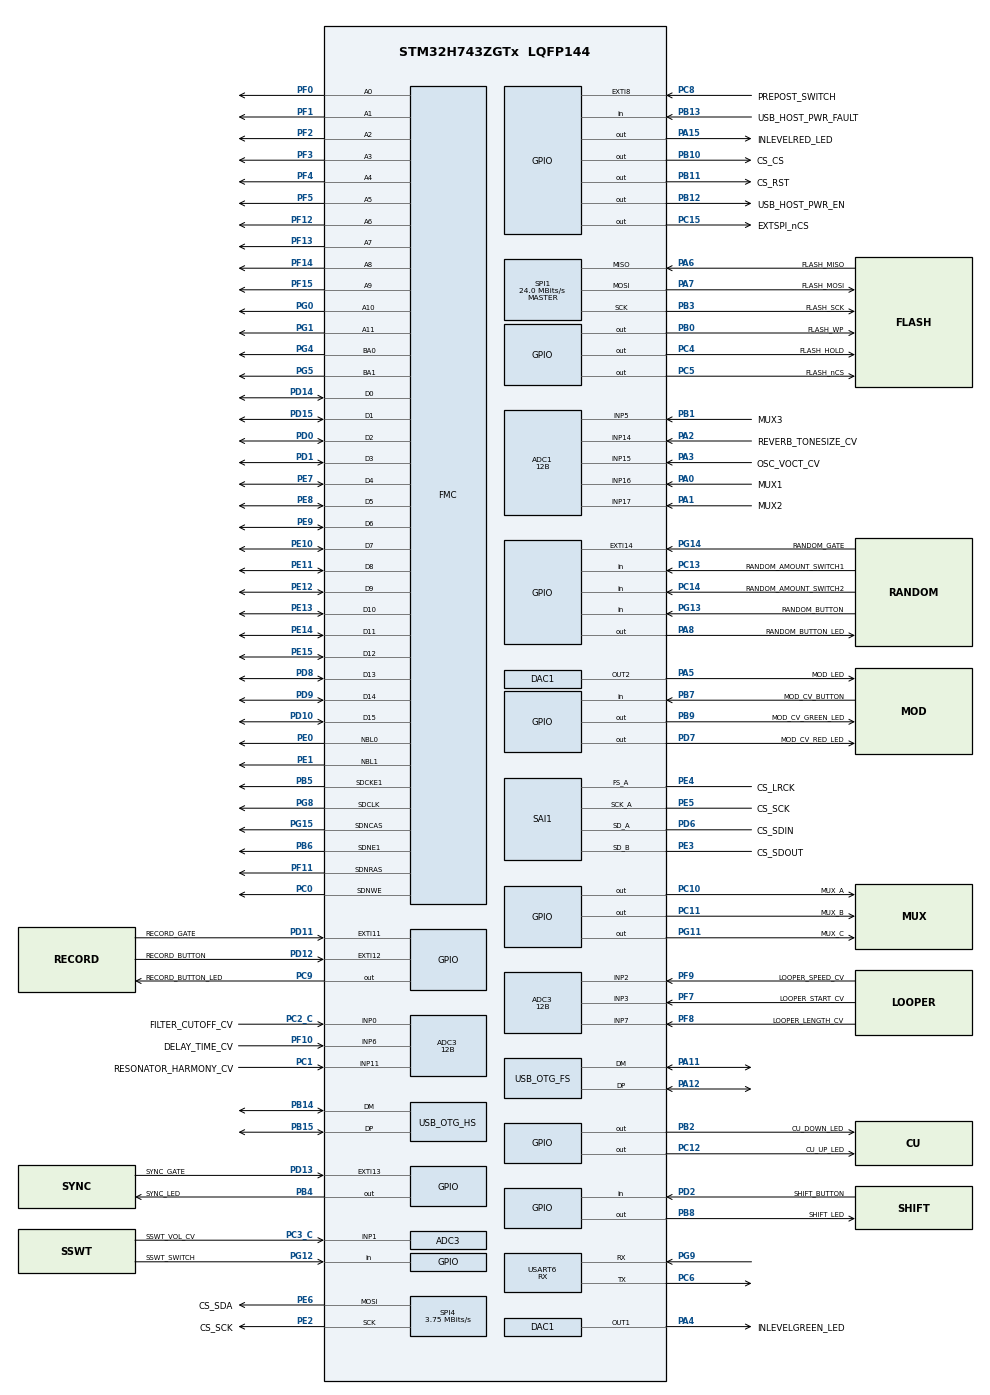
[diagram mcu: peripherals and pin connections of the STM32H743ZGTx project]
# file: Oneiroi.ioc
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ADC1.Channel-0\#ChannelRegularConversion=ADC_CHANNEL_14
ADC1.Channel-1\#ChannelRegularConversion=ADC_CHANNEL_15
ADC1.Channel-2\#ChannelRegularConversion=ADC_CHANNEL_16
ADC1.Channel-3\#ChannelRegularConversion=ADC_CHANNEL_17
ADC1.Channel-4\#ChannelRegularConversion=ADC_CHANNEL_5
ADC1.ClockPrescaler=ADC_CLOCK_ASYNC_DIV16
ADC1.ClockPrescalerADC3=ADC_CLOCK_ASYNC_DIV4
ADC1.ContinuousConvMode=ENABLE
ADC1.ConversionDataManagement=ADC_CONVERSIONDATA_DMA_CIRCULAR
ADC1.EOCSelection=ADC_EOC_SEQ_CONV
ADC1.NbrOfConversion=5
ADC1.NbrOfConversionFlag=1
ADC1.OffsetNumber-0\#ChannelRegularConversion=ADC_OFFSET_NONE
ADC1.OffsetNumber-1\#ChannelRegularConversion=ADC_OFFSET_NONE
ADC1.OffsetNumber-2\#ChannelRegularConversion=ADC_OFFSET_NONE
ADC1.OffsetNumber-3\#ChannelRegularConversion=ADC_OFFSET_NONE
ADC1.OffsetNumber-4\#ChannelRegularConversion=ADC_OFFSET_NONE
ADC1.OffsetSignedSaturation-0\#ChannelRegularConversion=DISABLE
ADC1.Overrun=ADC_OVR_DATA_OVERWRITTEN
ADC1.Rank-0\#ChannelRegularConversion=1
ADC1.Rank-1\#ChannelRegularConversion=2
ADC1.Rank-2\#ChannelRegularConversion=3
ADC1.Rank-3\#ChannelRegularConversion=4
ADC1.Rank-4\#ChannelRegularConversion=5
ADC1.Resolution=ADC_RESOLUTION_12B
ADC1.SamplingTime-0\#ChannelRegularConversion=ADC_SAMPLETIME_387CYCLES_5
ADC1.SamplingTime-1\#ChannelRegularConversion=ADC_SAMPLETIME_387CYCLES_5
ADC1.SamplingTime-2\#ChannelRegularConversion=ADC_SAMPLETIME_387CYCLES_5
ADC1.SamplingTime-3\#ChannelRegularConversion=ADC_SAMPLETIME_387CYCLES_5
ADC1.SamplingTime-4\#ChannelRegularConversion=ADC_SAMPLETIME_387CYCLES_5
ADC1.master=1
ADC3.Channel-10\#ChannelRegularConversion=ADC_CHANNEL_2
ADC3.Channel-4\#ChannelRegularConversion=ADC_CHANNEL_1
ADC3.Channel-5\#ChannelRegularConversion=ADC_CHANNEL_0
ADC3.Channel-6\#ChannelRegularConversion=ADC_CHANNEL_11
ADC3.Channel-7\#ChannelRegularConversion=ADC_CHANNEL_6
ADC3.Channel-8\#ChannelRegularConversion=ADC_CHANNEL_3
ADC3.Channel-9\#ChannelRegularConversion=ADC_CHANNEL_7
ADC3.ClockPrescaler=ADC_CLOCK_ASYNC_DIV16
ADC3.ClockPrescalerADC3=ADC_CLOCK_ASYNC_DIV4
ADC3.ContinuousConvMode=ENABLE
ADC3.ConversionDataManagement=ADC_CONVERSIONDATA_DMA_CIRCULAR
ADC3.EOCSelection=ADC_EOC_SEQ_CONV
ADC3.NbrOfConversion=7
ADC3.NbrOfConversionFlag=1
ADC3.OffsetNumber-10\#ChannelRegularConversion=ADC_OFFSET_NONE
ADC3.OffsetNumber-4\#ChannelRegularConversion=ADC_OFFSET_NONE
ADC3.OffsetNumber-5\#ChannelRegularConversion=ADC_OFFSET_NONE
ADC3.OffsetNumber-6\#ChannelRegularConversion=ADC_OFFSET_NONE
ADC3.OffsetNumber-7\#ChannelRegularConversion=ADC_OFFSET_NONE
ADC3.OffsetNumber-8\#ChannelRegularConversion=ADC_OFFSET_NONE
ADC3.OffsetNumber-9\#ChannelRegularConversion=ADC_OFFSET_NONE
ADC3.OffsetSignedSaturation-4\#ChannelRegularConversion=DISABLE
ADC3.Overrun=ADC_OVR_DATA_OVERWRITTEN
ADC3.Rank-10\#ChannelRegularConversion=7
ADC3.Rank-4\#ChannelRegularConversion=1
ADC3.Rank-5\#ChannelRegularConversion=2
ADC3.Rank-6\#ChannelRegularConversion=3
ADC3.Rank-7\#ChannelRegularConversion=4
ADC3.Rank-8\#ChannelRegularConversion=5
ADC3.Rank-9\#ChannelRegularConversion=6
ADC3.Resolution=ADC_RESOLUTION_12B
ADC3.SamplingTime-10\#ChannelRegularConversion=ADC_SAMPLETIME_387CYCLES_5
ADC3.SamplingTime-4\#ChannelRegularConversion=ADC_SAMPLETIME_387CYCLES_5
ADC3.SamplingTime-5\#ChannelRegularConversion=ADC_SAMPLETIME_387CYCLES_5
ADC3.SamplingTime-6\#ChannelRegularConversion=ADC_SAMPLETIME_387CYCLES_5
ADC3.SamplingTime-7\#ChannelRegularConversion=ADC_SAMPLETIME_387CYCLES_5
ADC3.SamplingTime-8\#ChannelRegularConversion=ADC_SAMPLETIME_387CYCLES_5
ADC3.SamplingTime-9\#ChannelRegularConversion=ADC_SAMPLETIME_387CYCLES_5
DAC1.DAC1_OutputBuffer-DAC_OUT1=DAC_OUTPUTBUFFER_ENABLE
DAC1.DAC2_OutputBuffer-DAC_OUT2=DAC_OUTPUTBUFFER_ENABLE
DAC1.DAC_Channel-DAC_OUT1=DAC_CHANNEL_1
DAC1.DAC_Channel-DAC_OUT2=DAC_CHANNEL_2
Dma.ADC1.2.Direction=DMA_PERIPH_TO_MEMORY
Dma.ADC1.2.EventEnable=DISABLE
Dma.ADC1.2.FIFOMode=DMA_FIFOMODE_DISABLE
Dma.ADC1.2.Instance=DMA1_Stream1
Dma.ADC1.2.MemDataAlignment=DMA_MDATAALIGN_HALFWORD
Dma.ADC1.2.MemInc=DMA_MINC_ENABLE
Dma.ADC1.2.Mode=DMA_CIRCULAR
Dma.ADC1.2.PeriphDataAlignment=DMA_PDATAALIGN_HALFWORD
Dma.ADC1.2.PeriphInc=DMA_PINC_DISABLE
Dma.ADC1.2.Polarity=HAL_DMAMUX_REQ_GEN_RISING
Dma.ADC1.2.Priority=DMA_PRIORITY_LOW
Dma.ADC1.2.RequestNumber=1
Dma.ADC1.2.SignalID=NONE
Dma.ADC1.2.SyncEnable=DISABLE
Dma.ADC1.2.SyncPolarity=HAL_DMAMUX_SYNC_NO_EVENT
Dma.ADC1.2.SyncRequestNumber=1
Dma.ADC1.2.SyncSignalID=NONE
Dma.ADC3.3.Direction=DMA_PERIPH_TO_MEMORY
Dma.ADC3.3.EventEnable=DISABLE
Dma.ADC3.3.FIFOMode=DMA_FIFOMODE_DISABLE
Dma.ADC3.3.Instance=DMA1_Stream0
Dma.ADC3.3.MemDataAlignment=DMA_MDATAALIGN_HALFWORD
Dma.ADC3.3.MemInc=DMA_MINC_ENABLE
Dma.ADC3.3.Mode=DMA_CIRCULAR
Dma.ADC3.3.PeriphDataAlignment=DMA_PDATAALIGN_HALFWORD
Dma.ADC3.3.PeriphInc=DMA_PINC_DISABLE
Dma.ADC3.3.Polarity=HAL_DMAMUX_REQ_GEN_RISING
Dma.ADC3.3.Priority=DMA_PRIORITY_LOW
Dma.ADC3.3.RequestNumber=1
Dma.ADC3.3.SignalID=NONE
Dma.ADC3.3.SyncEnable=DISABLE
Dma.ADC3.3.SyncPolarity=HAL_DMAMUX_SYNC_NO_EVENT
Dma.ADC3.3.SyncRequestNumber=1
Dma.ADC3.3.SyncSignalID=NONE
Dma.Request0=SAI1_A
Dma.Request1=SAI1_B
Dma.Request2=ADC1
Dma.Request3=ADC3
Dma.SAI1_A.0.Direction=DMA_MEMORY_TO_PERIPH
Dma.SAI1_A.0.EventEnable=DISABLE
Dma.SAI1_A.0.FIFOMode=DMA_FIFOMODE_DISABLE
Dma.SAI1_A.0.Instance=DMA2_Stream1
Dma.SAI1_A.0.MemDataAlignment=DMA_MDATAALIGN_WORD
Dma.SAI1_A.0.MemInc=DMA_MINC_ENABLE
Dma.SAI1_A.0.Mode=DMA_CIRCULAR
Dma.SAI1_A.0.PeriphDataAlignment=DMA_PDATAALIGN_WORD
Dma.SAI1_A.0.PeriphInc=DMA_PINC_DISABLE
Dma.SAI1_A.0.Polarity=HAL_DMAMUX_REQ_GEN_RISING
Dma.SAI1_A.0.Priority=DMA_PRIORITY_HIGH
Dma.SAI1_A.0.RequestNumber=1
Dma.SAI1_A.0.SignalID=NONE
Dma.SAI1_A.0.SyncEnable=DISABLE
Dma.SAI1_A.0.SyncPolarity=HAL_DMAMUX_SYNC_NO_EVENT
Dma.SAI1_A.0.SyncRequestNumber=1
Dma.SAI1_A.0.SyncSignalID=NONE
Dma.SAI1_B.1.Direction=DMA_PERIPH_TO_MEMORY
Dma.SAI1_B.1.EventEnable=DISABLE
Dma.SAI1_B.1.FIFOMode=DMA_FIFOMODE_DISABLE
Dma.SAI1_B.1.Instance=DMA2_Stream4
Dma.SAI1_B.1.MemDataAlignment=DMA_MDATAALIGN_WORD
Dma.SAI1_B.1.MemInc=DMA_MINC_ENABLE
Dma.SAI1_B.1.Mode=DMA_CIRCULAR
Dma.SAI1_B.1.PeriphDataAlignment=DMA_PDATAALIGN_WORD
Dma.SAI1_B.1.PeriphInc=DMA_PINC_DISABLE
Dma.SAI1_B.1.Polarity=HAL_DMAMUX_REQ_GEN_RISING
Dma.SAI1_B.1.Priority=DMA_PRIORITY_HIGH
Dma.SAI1_B.1.RequestNumber=1
Dma.SAI1_B.1.SignalID=NONE
Dma.SAI1_B.1.SyncEnable=DISABLE
Dma.SAI1_B.1.SyncPolarity=HAL_DMAMUX_SYNC_NO_EVENT
Dma.SAI1_B.1.SyncRequestNumber=1
Dma.SAI1_B.1.SyncSignalID=NONE
FMC.CASLatency1=FMC_SDRAM_CAS_LATENCY_3
FMC.ExitSelfRefreshDelay1=6
FMC.LoadToActiveDelay1=2
FMC.RCDDelay1=2
FMC.RPDelay1=2
FMC.ReadBurst1=FMC_SDRAM_RBURST_ENABLE
FMC.ReadPipeDelay1=FMC_SDRAM_RPIPE_DELAY_0
FMC.RowCycleDelay1=6
FMC.SDClockPeriod1=FMC_SDRAM_CLOCK_PERIOD_2
FMC.SelfRefreshTime1=4
FMC.WriteRecoveryTime1=2
FREERTOS.INCLUDE_vTaskDelayUntil=1
FREERTOS.MEMORY_ALLOCATION=2
FREERTOS.Tasks01=defaultTask,0,1024,StartDefaultTask,Default,NULL,Dynamic,NULL,NULL
FREERTOS.configCHECK_FOR_STACK_OVERFLOW=2
FREERTOS.configENABLE_BACKWARD_COMPATIBILITY=0
FREERTOS.configTOTAL_HEAP_SIZE=8192
FREERTOS.configUSE_MALLOC_FAILED_HOOK=1
FREERTOS.configUSE_MUTEXES=0
FREERTOS.configUSE_PREEMPTION=0
Mcu.Family=STM32H7
Mcu.Name=STM32H743ZGTx
Mcu.Package=LQFP144
NVIC.ADC3_IRQn=true\:5\:0\:false\:false\:true\:true\:true\:true\:true
NVIC.ADC_IRQn=true\:5\:0\:false\:false\:true\:true\:true\:true\:true
NVIC.DMA1_Stream0_IRQn=true\:5\:0\:false\:false\:true\:true\:false\:true\:true
NVIC.DMA1_Stream1_IRQn=true\:5\:0\:false\:false\:true\:true\:false\:true\:true
NVIC.DMA2_Stream1_IRQn=true\:5\:0\:true\:false\:true\:true\:true\:true\:true
NVIC.DMA2_Stream4_IRQn=true\:5\:0\:true\:false\:true\:true\:true\:true\:true
NVIC.EXTI15_10_IRQn=true\:15\:0\:true\:false\:true\:true\:true\:true\:true
NVIC.EXTI9_5_IRQn=true\:15\:0\:true\:false\:true\:true\:true\:true\:true
NVIC.OTG_FS_IRQn=true\:10\:0\:true\:false\:true\:true\:true\:true\:true
NVIC.OTG_HS_IRQn=true\:10\:0\:true\:false\:true\:true\:true\:true\:true
NVIC.PriorityGroup=NVIC_PRIORITYGROUP_4
PA0.GPIO_Label=MUX1
PA0.Mode=IN16-Single-Ended
PA0.Signal=ADC1_INP16
PA1.GPIO_Label=MUX2
PA1.Mode=IN17-Single-Ended
PA1.Signal=ADC1_INP17
PA11.Mode=Device_Only
PA11.Signal=USB_OTG_FS_DM
PA12.Mode=Device_Only
PA12.Signal=USB_OTG_FS_DP
PA13\ (JTMS/SWDIO).Mode=Serial_Wire
PA13\ (JTMS/SWDIO).Signal=DEBUG_JTMS-SWDIO
PA14\ (JTCK/SWCLK).Mode=Serial_Wire
PA14\ (JTCK/SWCLK).Signal=DEBUG_JTCK-SWCLK
PA15\ (JTDI).GPIO_Label=INLEVELRED_LED
PA15\ (JTDI).Signal=GPIO_Output
PA2.GPIO_Label=REVERB_TONESIZE_CV
PA2.Signal=ADCx_INP14
PA3.GPIO_Label=OSC_VOCT_CV
PA3.Signal=ADCx_INP15
PA4.GPIO_Label=INLEVELGREEN_LED
PA4.Signal=COMP_DAC11_group
PA5.GPIO_Label=MOD_LED
PA5.Signal=COMP_DAC12_group
PA6.GPIO_Label=FLASH_MISO
PA6.Mode=Full_Duplex_Master
PA6.Signal=SPI1_MISO
PA7.GPIO_Label=FLASH_MOSI
PA7.Mode=Full_Duplex_Master
PA7.Signal=SPI1_MOSI
PA8.GPIO_Label=RANDOM_BUTTON_LED
PA8.Signal=GPIO_Output
PB0.GPIO_Label=FLASH_WP
PB0.Signal=GPIO_Output
PB1.GPIO_Label=MUX3
PB1.Signal=ADCx_INP5
PB10.GPIO_Label=CS_CS
PB10.Signal=GPIO_Output
PB11.GPIO_Label=CS_RST
PB11.Signal=GPIO_Output
PB12.GPIO_Label=USB_HOST_PWR_EN
PB12.Signal=GPIO_Output
PB13.GPIO_Label=USB_HOST_PWR_FAULT
PB13.GPIO_PuPd=GPIO_PULLUP
PB13.Signal=GPIO_Input
PB14.Mode=Host_FS
PB14.Signal=USB_OTG_HS_DM
PB15.Mode=Host_FS
PB15.Signal=USB_OTG_HS_DP
PB2.GPIO_Label=CU_DOWN_LED
PB2.Signal=GPIO_Output
PB3\ (JTDO/TRACESWO).GPIO_Label=FLASH_SCK
PB3\ (JTDO/TRACESWO).Mode=Full_Duplex_Master
PB3\ (JTDO/TRACESWO).Signal=SPI1_SCK
PB4\ (NJTRST).GPIO_Label=SYNC_LED
PB4\ (NJTRST).Signal=GPIO_Output
PB5.Mode=SdramChipSelect2_1
PB5.Signal=FMC_SDCKE1
PB6.Mode=SdramChipSelect2_1
PB6.Signal=FMC_SDNE1
PB7.GPIO_Label=MOD_CV_BUTTON
PB7.GPIO_PuPd=GPIO_PULLUP
PB7.Signal=GPIO_Input
PB8.GPIO_Label=SHIFT_LED
PB8.Signal=GPIO_Output
PB9.GPIO_Label=MOD_CV_GREEN_LED
PB9.Signal=GPIO_Output
PC0.Signal=FMC_SDNWE
PC1.GPIO_Label=RESONATOR_HARMONY_CV
PC1.Signal=ADCx_INP11
PC10.GPIO_Label=MUX_A
PC10.Signal=GPIO_Output
PC11.GPIO_Label=MUX_B
PC11.Signal=GPIO_Output
PC12.GPIO_Label=CU_UP_LED
PC12.Signal=GPIO_Output
PC13.GPIO_Label=RANDOM_AMOUNT_SWITCH1
PC13.GPIO_PuPd=GPIO_PULLUP
PC13.Signal=GPIO_Input
PC14-OSC32_IN\ (OSC32_IN).GPIO_Label=RANDOM_AMOUNT_SWITCH2
PC14-OSC32_IN\ (OSC32_IN).GPIO_PuPd=GPIO_PULLUP
PC14-OSC32_IN\ (OSC32_IN).Signal=GPIO_Input
PC15-OSC32_OUT\ (OSC32_OUT).GPIO_Label=EXTSPI_nCS
PC15-OSC32_OUT\ (OSC32_OUT).Signal=GPIO_Output
PC2_C.GPIO_Label=FILTER_CUTOFF_CV
PC2_C.Mode=IN0-Single-Ended
PC2_C.Signal=ADC3_INP0
PC3_C.GPIO_Label=SSWT_VOL_CV
PC3_C.Mode=IN1-Single-Ended
PC3_C.Signal=ADC3_INP1
PC4.GPIO_Label=FLASH_HOLD
PC4.Signal=GPIO_Output
PC5.GPIO_Label=FLASH_nCS
PC5.Signal=GPIO_Output
PC6.Mode=Asynchronous
PC6.Signal=USART6_TX
PC8.GPIO_Label=PREPOST_SWITCH
PC8.GPIO_ModeDefaultEXTI=GPIO_MODE_IT_RISING_FALLING
PC8.GPIO_PuPd=GPIO_PULLUP
PC8.Signal=GPXTI8
PC9.GPIO_Label=RECORD_BUTTON_LED
PC9.Signal=GPIO_Output
PD0.Signal=FMC_D2_DA2
PD1.Signal=FMC_D3_DA3
PD10.Signal=FMC_D15_DA15
PD11.GPIO_Label=RECORD_GATE
PD11.GPIO_ModeDefaultEXTI=GPIO_MODE_IT_RISING_FALLING
PD11.GPIO_PuPd=GPIO_PULLUP
PD11.Signal=GPXTI11
PD12.GPIO_Label=RECORD_BUTTON
PD12.GPIO_ModeDefaultEXTI=GPIO_MODE_IT_RISING_FALLING
PD12.GPIO_PuPd=GPIO_PULLUP
PD12.Signal=GPXTI12
PD13.GPIO_Label=SYNC_GATE
PD13.GPIO_ModeDefaultEXTI=GPIO_MODE_IT_RISING_FALLING
PD13.GPIO_PuPd=GPIO_PULLUP
PD13.Signal=GPXTI13
PD14.Signal=FMC_D0_DA0
PD15.Signal=FMC_D1_DA1
PD2.GPIO_Label=SHIFT_BUTTON
PD2.GPIO_PuPd=GPIO_PULLUP
PD2.Signal=GPIO_Input
PD6.GPIO_Label=CS_SDIN
PD6.GPIO_Speed=GPIO_SPEED_FREQ_VERY_HIGH
PD6.Mode=SAI_A_AsyncSlave
PD6.Signal=SAI1_SD_A
PD7.GPIO_Label=MOD_CV_RED_LED
PD7.Signal=GPIO_Output
PD8.Signal=FMC_D13_DA13
PD9.Signal=FMC_D14_DA14
PE0.Signal=FMC_NBL0
PE1.Signal=FMC_NBL1
PE10.Signal=FMC_D7_DA7
PE11.Signal=FMC_D8_DA8
PE12.Signal=FMC_D9_DA9
PE13.Signal=FMC_D10_DA10
PE14.Signal=FMC_D11_DA11
PE15.Signal=FMC_D12_DA12
PE2.GPIO_Label=CS_SCK
PE2.Mode=TX_Only_Simplex_Unidirect_Master
PE2.Signal=SPI4_SCK
PE3.GPIO_Label=CS_SDOUT
PE3.GPIO_Speed=GPIO_SPEED_FREQ_VERY_HIGH
PE3.Mode=SAI_B_SyncSlave
PE3.Signal=SAI1_SD_B
PE4.GPIO_Label=CS_LRCK
PE4.GPIO_Speed=GPIO_SPEED_FREQ_VERY_HIGH
PE4.Mode=SAI_A_AsyncSlave
PE4.Signal=SAI1_FS_A
PE5.GPIO_Label=CS_SCK
PE5.GPIO_Speed=GPIO_SPEED_FREQ_VERY_HIGH
PE5.Mode=SAI_A_AsyncSlave
PE5.Signal=SAI1_SCK_A
PE6.GPIO_Label=CS_SDA
PE6.Mode=TX_Only_Simplex_Unidirect_Master
PE6.Signal=SPI4_MOSI
PE7.Signal=FMC_D4_DA4
PE8.Signal=FMC_D5_DA5
PE9.Signal=FMC_D6_DA6
PF0.Signal=FMC_A0
PF1.Signal=FMC_A1
PF10.GPIO_Label=DELAY_TIME_CV
PF10.Mode=IN6-Single-Ended
PF10.Signal=ADC3_INP6
PF11.Signal=FMC_SDNRAS
PF12.Signal=FMC_A6
PF13.Signal=FMC_A7
PF14.Signal=FMC_A8
PF15.Signal=FMC_A9
PF2.Signal=FMC_A2
PF3.Signal=FMC_A3
PF4.Signal=FMC_A4
PF5.Signal=FMC_A5
PF7.GPIO_Label=LOOPER_START_CV
PF7.Mode=IN3-Single-Ended
PF7.Signal=ADC3_INP3
PF8.GPIO_Label=LOOPER_LENGTH_CV
PF8.Mode=IN7-Single-Ended
PF8.Signal=ADC3_INP7
PF9.GPIO_Label=LOOPER_SPEED_CV
PF9.Mode=IN2-Single-Ended
PF9.Signal=ADC3_INP2
PG0.Signal=FMC_A10
PG1.Signal=FMC_A11
PG11.GPIO_Label=MUX_C
PG11.Signal=GPIO_Output
PG12.GPIO_Label=SSWT_SWITCH
PG12.GPIO_PuPd=GPIO_PULLUP
PG12.Signal=GPIO_Input
PG13.GPIO_Label=RANDOM_BUTTON
PG13.GPIO_PuPd=GPIO_PULLUP
PG13.Signal=GPIO_Input
PG14.GPIO_Label=RANDOM_GATE
PG14.GPIO_ModeDefaultEXTI=GPIO_MODE_IT_RISING_FALLING
PG14.GPIO_PuPd=GPIO_PULLUP
PG14.Signal=GPXTI14
PG15.Signal=FMC_SDNCAS
PG4.Signal=FMC_A14_BA0
PG5.Signal=FMC_A15_BA1
PG8.Signal=FMC_SDCLK
PG9.Mode=Asynchronous
PG9.Signal=USART6_RX
PH0-OSC_IN\ (PH0).GPIO_Label=OSC1
PH0-OSC_IN\ (PH0).Mode=HSE-External-Oscillator
PH0-OSC_IN\ (PH0).Signal=RCC_OSC_IN
PH1-OSC_OUT\ (PH1).GPIO_Label=OSC2
PH1-OSC_OUT\ (PH1).Mode=HSE-External-Oscillator
PH1-OSC_OUT\ (PH1).Signal=RCC_OSC_OUT
ProjectManager.HeapSize=0x200
ProjectManager.StackSize=0x400
ProjectManager.TargetToolchain=Makefile
RCC.48MHZClocksFreq_Value=48000000
RCC.ADCFreq_Value=30000000
RCC.AHBFreq_Value=168000000
RCC.APB1CLKDivider=RCC_HCLK_DIV4
RCC.APB1Freq_Value=120000000
RCC.APB1TimFreq_Value=84000000
RCC.APB2CLKDivider=RCC_HCLK_DIV2
RCC.APB2Freq_Value=120000000
RCC.APB2TimFreq_Value=168000000
RCC.APB3Freq_Value=120000000
RCC.APB4Freq_Value=120000000
RCC.CortexFreq_Value=480000000
RCC.D1PPRE=RCC_APB3_DIV2
RCC.D2PPRE1=RCC_APB1_DIV2
RCC.D2PPRE2=RCC_APB2_DIV2
RCC.D3PPRE=RCC_APB4_DIV2
RCC.DIVM1=5
RCC.DIVM2=2
RCC.DIVN1=192
RCC.DIVN2=12
RCC.DIVP2=5
RCC.DIVQ1=20
RCC.HCLKFreq_Value=240000000
RCC.HPRE=RCC_HCLK_DIV2
RCC.HSE_VALUE=25000000
RCC.HSI_VALUE=16000000
RCC.LSE_VALUE=32768
RCC.PLLFRACN=0
RCC.PLLM=25
RCC.PLLN=336
RCC.PLLQ=7
RCC.PLLSAIN=100
RCC.SYSCLKFreq_VALUE=480000000
RCC.SYSCLKSource=RCC_SYSCLKSOURCE_PLLCLK
RCC.USBFreq_Value=48000000
RCC.VCOOutputFreq_Value=336000000
SAI1.AudioMode-SAI_A_AsyncSlave=SAI_MODESLAVE_TX
SAI1.BasicDataSize-SAI_A_AsyncSlave=SAI_PROTOCOL_DATASIZE_24BIT
SAI1.BasicDataSize-SAI_B_SyncSlave=SAI_PROTOCOL_DATASIZE_24BIT
SAI1.InitProtocol-SAI_A_AsyncSlave=Enable
SAI1.InitProtocol-SAI_B_SyncSlave=Enable
SAI1.Instance-SAI_A_AsyncSlave=SAI$Index_Block_A
SAI1.Instance-SAI_B_SyncSlave=SAI$Index_Block_B
SAI1.VirtualMode-SAI_A_AsyncSlave=VM_SLAVE
SAI1.VirtualMode-SAI_B_SyncSlave=VM_SLAVE
SAI1.VirtualProtocol-SAI_A_BASIC=VM_BASIC_PROTOCOL
SAI1.VirtualProtocol-SAI_B_BASIC=VM_BASIC_PROTOCOL
SH.ADCx_INP11.0=ADC3_INP11,IN11-Single-Ended
SH.ADCx_INP14.0=ADC1_INP14,IN14-Single-Ended
SH.ADCx_INP15.0=ADC1_INP15,IN15-Single-Ended
SH.ADCx_INP5.0=ADC1_INP5,IN5-Single-Ended
SH.COMP_DAC11_group.0=DAC1_OUT1,DAC_OUT1
SH.COMP_DAC12_group.0=DAC1_OUT2,DAC_OUT2
SH.FMC_A0.0=FMC_A0,12b-sda1
SH.FMC_A1.0=FMC_A1,12b-sda1
SH.FMC_A10.0=FMC_A10,12b-sda1
SH.FMC_A11.0=FMC_A11,12b-sda1
SH.FMC_A14_BA0.0=FMC_BA0,FourSdramBanks1
SH.FMC_A15_BA1.0=FMC_BA1,FourSdramBanks1
SH.FMC_A2.0=FMC_A2,12b-sda1
SH.FMC_A3.0=FMC_A3,12b-sda1
SH.FMC_A4.0=FMC_A4,12b-sda1
SH.FMC_A5.0=FMC_A5,12b-sda1
SH.FMC_A6.0=FMC_A6,12b-sda1
SH.FMC_A7.0=FMC_A7,12b-sda1
SH.FMC_A8.0=FMC_A8,12b-sda1
SH.FMC_A9.0=FMC_A9,12b-sda1
SH.FMC_D0_DA0.0=FMC_D0,sd-16b-d1
SH.FMC_D10_DA10.0=FMC_D10,sd-16b-d1
SH.FMC_D11_DA11.0=FMC_D11,sd-16b-d1
SH.FMC_D12_DA12.0=FMC_D12,sd-16b-d1
SH.FMC_D13_DA13.0=FMC_D13,sd-16b-d1
SH.FMC_D14_DA14.0=FMC_D14,sd-16b-d1
SH.FMC_D15_DA15.0=FMC_D15,sd-16b-d1
SH.FMC_D1_DA1.0=FMC_D1,sd-16b-d1
SH.FMC_D2_DA2.0=FMC_D2,sd-16b-d1
SH.FMC_D3_DA3.0=FMC_D3,sd-16b-d1
SH.FMC_D4_DA4.0=FMC_D4,sd-16b-d1
SH.FMC_D5_DA5.0=FMC_D5,sd-16b-d1
SH.FMC_D6_DA6.0=FMC_D6,sd-16b-d1
SH.FMC_D7_DA7.0=FMC_D7,sd-16b-d1
SH.FMC_D8_DA8.0=FMC_D8,sd-16b-d1
SH.FMC_D9_DA9.0=FMC_D9,sd-16b-d1
SH.FMC_NBL0.0=FMC_NBL0,Sd2ByteEnable1
SH.FMC_NBL1.0=FMC_NBL1,Sd2ByteEnable1
SH.FMC_SDCLK.0=FMC_SDCLK,12b-sda1
SH.FMC_SDNCAS.0=FMC_SDNCAS,12b-sda1
SH.FMC_SDNRAS.0=FMC_SDNRAS,12b-sda1
SH.FMC_SDNWE.0=FMC_SDNWE,12b-sda1
SPI1.BaudRatePrescaler=SPI_BAUDRATEPRESCALER_2
SPI1.CalculateBaudRate=24.0 MBits/s
SPI1.DataSize=SPI_DATASIZE_8BIT
SPI1.Direction=SPI_DIRECTION_2LINES
SPI1.Mode=SPI_MODE_MASTER
SPI1.NSSPMode=SPI_NSS_PULSE_DISABLE
SPI1.VirtualType=VM_MASTER
SPI4.BaudRatePrescaler=SPI_BAUDRATEPRESCALER_32
SPI4.CalculateBaudRate=3.75 MBits/s
SPI4.DataSize=SPI_DATASIZE_8BIT
SPI4.Direction=SPI_DIRECTION_2LINES_TXONLY
SPI4.Mode=SPI_MODE_MASTER
SPI4.NSSPMode=SPI_NSS_PULSE_DISABLE
SPI4.VirtualType=VM_MASTER
USART6.Mode=MODE_RX
USART6.VirtualMode-Asynchronous=VM_ASYNC
USB_OTG_FS.VirtualMode=Device_Only
USB_OTG_HS.VirtualMode-Host_FS=Host_FS
VP_FREERTOS_VS_CMSIS_V1.Mode=CMSIS_V1
VP_RTC_VS_RTC_Activate.Mode=RTC_Enabled
VP_SAI1_VP_$IpInstance_SAIA_SAI_BASIC.Mode=SAI_A_BASIC
VP_SAI1_VP_$IpInstance_SAIB_SAI_BASIC.Mode=SAI_B_BASIC
board=custom

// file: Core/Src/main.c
/* USER CODE BEGIN Header */
/**
  ******************************************************************************
  * @file           : main.c
  * @brief          : Main program body
  ******************************************************************************
  * @attention
  *
  * Copyright (c) 2023 STMicroelectronics.
  * All rights reserved.
  *
  * This software is licensed under terms that can be found in the LICENSE file
  * in the root directory of this software component.
  * If no LICENSE file comes with this software, it is provided AS-IS.
  *
  ******************************************************************************
  */
/* USER CODE END Header */
#include "main.h"
#include "cmsis_os.h"

/* USER CODE BEGIN Includes */

#include "errorhandlers.h"  // 5/6/2023

#ifdef DEBUG
#include <stdio.h>
#endif

/* USER CODE END Includes */

ADC_HandleTypeDef hadc1;
ADC_HandleTypeDef hadc3;
DMA_HandleTypeDef hdma_adc1;
DMA_HandleTypeDef hdma_adc3;

DAC_HandleTypeDef hdac1;

RTC_HandleTypeDef hrtc;

SAI_HandleTypeDef hsai_BlockA1;
SAI_HandleTypeDef hsai_BlockB1;
DMA_HandleTypeDef hdma_sai1_a;
DMA_HandleTypeDef hdma_sai1_b;

SPI_HandleTypeDef hspi1;
SPI_HandleTypeDef hspi4;

UART_HandleTypeDef huart6;

PCD_HandleTypeDef hpcd_USB_OTG_FS;
HCD_HandleTypeDef hhcd_USB_OTG_HS;

SDRAM_HandleTypeDef hsdram1;

osThreadId defaultTaskHandle;

void SystemClock_Config(void);
void PeriphCommonClock_Config(void);
static void MX_GPIO_Init(void);
static void MX_DMA_Init(void);
static void MX_RTC_Init(void);
static void MX_SPI1_Init(void);
static void MX_SPI4_Init(void);
static void MX_USB_OTG_FS_PCD_Init(void);
static void MX_USB_OTG_HS_HCD_Init(void);
static void MX_SAI1_Init(void);
static void MX_ADC3_Init(void);
static void MX_DAC1_Init(void);
static void MX_FMC_Init(void);
static void MX_USART6_UART_Init(void);
static void MX_ADC1_Init(void);
void StartDefaultTask(void const * argument);

/* USER CODE BEGIN PFP */
/* Private function prototypes -----------------------------------------------*/

void setup(void);
void loop(void);
void SDRAM_Initialization_Sequence(SDRAM_HandleTypeDef *hsdram);
void initialise_monitor_handles(void);
void MPU_Config(void);

/* USER CODE END PFP */

int main(void)
{
  /* USER CODE BEGIN 1 */

#ifdef DEBUG
#warning "DEBUG uses printf and semihosting!"
  if(CoreDebug->DHCSR & 0x01)
    initialise_monitor_handles(); // remove when not semi-hosting
  printf("showtime\n");
#endif
#ifdef USE_ICACHE
  /* Enable I-Cache-------------------------------------------------------------*/
  /* After reset, you must invalidate each cache before enabling (SCB_EnableICache) it. */
  SCB_InvalidateICache();
  SCB_EnableICache();
#endif
#ifdef USE_DCACHE
  /* Enable D-Cache-------------------------------------------------------------*/
  /* Before enabling the data cache, you must invalidate the entire data cache (SCB_InvalidateDCache), because external memory might have changed from when the cache was disabled. */
  SCB_InvalidateDCache();
  SCB_EnableDCache();
#endif

  /* Enable D2 domain SRAM Clocks */
  __HAL_RCC_D2SRAM1_CLK_ENABLE();
  __HAL_RCC_D2SRAM2_CLK_ENABLE();
  __HAL_RCC_D2SRAM3_CLK_ENABLE();

  /* USER CODE END 1 */

  /* MCU Configuration--------------------------------------------------------*/

  /* Reset of all peripherals, Initializes the Flash interface and the Systick. */
  HAL_Init();

  /* Configure the system clock */
  SystemClock_Config();

/* Configure the peripherals common clocks */
  PeriphCommonClock_Config();

  /* USER CODE BEGIN SysInit */

  /* MPU Configuration--------------------------------------------------------*/
  MPU_Config();

  /* USER CODE END SysInit */

  /* Initialize all configured peripherals */
  MX_GPIO_Init();
  MX_DMA_Init();
  MX_RTC_Init();
  MX_SPI1_Init();
  MX_SPI4_Init();
  MX_USB_OTG_FS_PCD_Init();
  MX_USB_OTG_HS_HCD_Init();
  MX_SAI1_Init();
  MX_ADC3_Init();
  MX_DAC1_Init();
  MX_FMC_Init();
  MX_USART6_UART_Init();
  MX_ADC1_Init();
  /* USER CODE BEGIN 2 */

  HAL_SAI_DeInit(&hsai_BlockA1);
  HAL_SAI_DeInit(&hsai_BlockB1);
  hsai_BlockA1.Instance = SAI1_Block_A;
  hsai_BlockA1.Init.AudioMode = SAI_MODESLAVE_TX;
  hsai_BlockA1.Init.Synchro = SAI_ASYNCHRONOUS;
  hsai_BlockA1.Init.OutputDrive = SAI_OUTPUTDRIVE_DISABLE;
  hsai_BlockA1.Init.FIFOThreshold = SAI_FIFOTHRESHOLD_EMPTY;
  hsai_BlockA1.Init.SynchroExt = SAI_SYNCEXT_DISABLE;
  hsai_BlockA1.Init.MonoStereoMode = SAI_STEREOMODE;
  hsai_BlockA1.Init.CompandingMode = SAI_NOCOMPANDING;
  hsai_BlockA1.Init.TriState = SAI_OUTPUT_NOTRELEASED;
  if(HAL_SAI_InitProtocol(&hsai_BlockA1, SAI_I2S_STANDARD,
                          SAI_PROTOCOL_DATASIZE_24BIT, 2) != HAL_OK)
    Error_Handler();
  hsai_BlockB1.Instance = SAI1_Block_B;
  hsai_BlockB1.Init.AudioMode = SAI_MODESLAVE_RX;
  hsai_BlockB1.Init.Synchro = SAI_SYNCHRONOUS;
  hsai_BlockB1.Init.OutputDrive = SAI_OUTPUTDRIVE_DISABLE;
  hsai_BlockB1.Init.FIFOThreshold = SAI_FIFOTHRESHOLD_EMPTY;
  hsai_BlockB1.Init.SynchroExt = SAI_SYNCEXT_DISABLE;
  hsai_BlockB1.Init.MonoStereoMode = SAI_STEREOMODE;
  hsai_BlockB1.Init.CompandingMode = SAI_NOCOMPANDING;
  hsai_BlockB1.Init.TriState = SAI_OUTPUT_NOTRELEASED;
  if(HAL_SAI_InitProtocol(&hsai_BlockB1, SAI_I2S_STANDARD,
                          SAI_PROTOCOL_DATASIZE_24BIT, 2) != HAL_OK)
    Error_Handler();

#ifdef USE_EXTERNAL_RAM
  SDRAM_Initialization_Sequence(&hsdram1);
#endif

  /* USER CODE END 2 */

  /* Create the thread(s) */
  /* definition and creation of defaultTask */
  osThreadDef(defaultTask, StartDefaultTask, osPriorityNormal, 0, 1024);
  defaultTaskHandle = osThreadCreate(osThread(defaultTask), NULL);

  /* Start scheduler */
  osKernelStart();

  /* We should never get here as control is now taken by the scheduler */
  /* Infinite loop */
  while (1)
  {

  }
}

void SystemClock_Config(void)
{
  RCC_OscInitTypeDef RCC_OscInitStruct = {0};
  RCC_ClkInitTypeDef RCC_ClkInitStruct = {0};

  /** Supply configuration update enable
  */
  HAL_PWREx_ConfigSupply(PWR_LDO_SUPPLY);

  /** Configure the main internal regulator output voltage
  */
  __HAL_PWR_VOLTAGESCALING_CONFIG(PWR_REGULATOR_VOLTAGE_SCALE1);

  while(!__HAL_PWR_GET_FLAG(PWR_FLAG_VOSRDY)) {}

  __HAL_RCC_SYSCFG_CLK_ENABLE();
  __HAL_PWR_VOLTAGESCALING_CONFIG(PWR_REGULATOR_VOLTAGE_SCALE0);

  while(!__HAL_PWR_GET_FLAG(PWR_FLAG_VOSRDY)) {}

  /** Macro to configure the PLL clock source
  */
  __HAL_RCC_PLL_PLLSOURCE_CONFIG(RCC_PLLSOURCE_HSE);

  /** Initializes the RCC Oscillators according to the specified parameters
  * in the RCC_OscInitTypeDef structure.
  */
  RCC_OscInitStruct.OscillatorType = RCC_OSCILLATORTYPE_LSI|RCC_OSCILLATORTYPE_HSE;
  RCC_OscInitStruct.HSEState = RCC_HSE_ON;
  RCC_OscInitStruct.LSIState = RCC_LSI_ON;
  RCC_OscInitStruct.PLL.PLLState = RCC_PLL_ON;
  RCC_OscInitStruct.PLL.PLLSource = RCC_PLLSOURCE_HSE;
  RCC_OscInitStruct.PLL.PLLM = 5;
  RCC_OscInitStruct.PLL.PLLN = 192;
  RCC_OscInitStruct.PLL.PLLP = 2;
  RCC_OscInitStruct.PLL.PLLQ = 20;
  RCC_OscInitStruct.PLL.PLLR = 2;
  RCC_OscInitStruct.PLL.PLLRGE = RCC_PLL1VCIRANGE_2;
  RCC_OscInitStruct.PLL.PLLVCOSEL = RCC_PLL1VCOWIDE;
  RCC_OscInitStruct.PLL.PLLFRACN = 0;
  if (HAL_RCC_OscConfig(&RCC_OscInitStruct) != HAL_OK)
  {
    Error_Handler();
  }

  /** Initializes the CPU, AHB and APB buses clocks
  */
  RCC_ClkInitStruct.ClockType = RCC_CLOCKTYPE_HCLK|RCC_CLOCKTYPE_SYSCLK
                              |RCC_CLOCKTYPE_PCLK1|RCC_CLOCKTYPE_PCLK2
                              |RCC_CLOCKTYPE_D3PCLK1|RCC_CLOCKTYPE_D1PCLK1;
  RCC_ClkInitStruct.SYSCLKSource = RCC_SYSCLKSOURCE_PLLCLK;
  RCC_ClkInitStruct.SYSCLKDivider = RCC_SYSCLK_DIV1;
  RCC_ClkInitStruct.AHBCLKDivider = RCC_HCLK_DIV2;
  RCC_ClkInitStruct.APB3CLKDivider = RCC_APB3_DIV2;
  RCC_ClkInitStruct.APB1CLKDivider = RCC_APB1_DIV2;
  RCC_ClkInitStruct.APB2CLKDivider = RCC_APB2_DIV2;
  RCC_ClkInitStruct.APB4CLKDivider = RCC_APB4_DIV2;

  if (HAL_RCC_ClockConfig(&RCC_ClkInitStruct, FLASH_LATENCY_4) != HAL_OK)
  {
    Error_Handler();
  }
}

void PeriphCommonClock_Config(void)
{
  RCC_PeriphCLKInitTypeDef PeriphClkInitStruct = {0};

  /** Initializes the peripherals clock
  */
  PeriphClkInitStruct.PeriphClockSelection = RCC_PERIPHCLK_ADC;
  PeriphClkInitStruct.PLL2.PLL2M = 2;
  PeriphClkInitStruct.PLL2.PLL2N = 12;
  PeriphClkInitStruct.PLL2.PLL2P = 5;
  PeriphClkInitStruct.PLL2.PLL2Q = 2;
  PeriphClkInitStruct.PLL2.PLL2R = 2;
  PeriphClkInitStruct.PLL2.PLL2RGE = RCC_PLL2VCIRANGE_3;
  PeriphClkInitStruct.PLL2.PLL2VCOSEL = RCC_PLL2VCOMEDIUM;
  PeriphClkInitStruct.PLL2.PLL2FRACN = 0;
  PeriphClkInitStruct.AdcClockSelection = RCC_ADCCLKSOURCE_PLL2;
  if (HAL_RCCEx_PeriphCLKConfig(&PeriphClkInitStruct) != HAL_OK)
  {
    Error_Handler();
  }
}

static void MX_ADC1_Init(void)
{

  ADC_MultiModeTypeDef multimode = {0};
  ADC_ChannelConfTypeDef sConfig = {0};

  /** Common config
  */
  hadc1.Instance = ADC1;
  hadc1.Init.ClockPrescaler = ADC_CLOCK_ASYNC_DIV16;
  hadc1.Init.Resolution = ADC_RESOLUTION_12B;
  hadc1.Init.ScanConvMode = ADC_SCAN_ENABLE;
  hadc1.Init.EOCSelection = ADC_EOC_SEQ_CONV;
  hadc1.Init.LowPowerAutoWait = DISABLE;
  hadc1.Init.ContinuousConvMode = ENABLE;
  hadc1.Init.NbrOfConversion = 5;
  hadc1.Init.DiscontinuousConvMode = DISABLE;
  hadc1.Init.ExternalTrigConv = ADC_SOFTWARE_START;
  hadc1.Init.ExternalTrigConvEdge = ADC_EXTERNALTRIGCONVEDGE_NONE;
  hadc1.Init.ConversionDataManagement = ADC_CONVERSIONDATA_DMA_CIRCULAR;
  hadc1.Init.Overrun = ADC_OVR_DATA_OVERWRITTEN;
  hadc1.Init.LeftBitShift = ADC_LEFTBITSHIFT_NONE;
  hadc1.Init.OversamplingMode = DISABLE;
  if (HAL_ADC_Init(&hadc1) != HAL_OK)
  {
    Error_Handler();
  }

  /** Configure the ADC multi-mode
  */
  multimode.Mode = ADC_MODE_INDEPENDENT;
  if (HAL_ADCEx_MultiModeConfigChannel(&hadc1, &multimode) != HAL_OK)
  {
    Error_Handler();
  }

  /** Configure Regular Channel
  */
  sConfig.Channel = ADC_CHANNEL_14;
  sConfig.Rank = ADC_REGULAR_RANK_1;
  sConfig.SamplingTime = ADC_SAMPLETIME_387CYCLES_5;
  sConfig.SingleDiff = ADC_SINGLE_ENDED;
  sConfig.OffsetNumber = ADC_OFFSET_NONE;
  sConfig.Offset = 0;
  sConfig.OffsetSignedSaturation = DISABLE;
  if (HAL_ADC_ConfigChannel(&hadc1, &sConfig) != HAL_OK)
  {
    Error_Handler();
  }

  /** Configure Regular Channel
  */
  sConfig.Channel = ADC_CHANNEL_15;
  sConfig.Rank = ADC_REGULAR_RANK_2;
  if (HAL_ADC_ConfigChannel(&hadc1, &sConfig) != HAL_OK)
  {
    Error_Handler();
  }

  /** Configure Regular Channel
  */
  sConfig.Channel = ADC_CHANNEL_16;
  sConfig.Rank = ADC_REGULAR_RANK_3;
  if (HAL_ADC_ConfigChannel(&hadc1, &sConfig) != HAL_OK)
  {
    Error_Handler();
  }

  /** Configure Regular Channel
  */
  sConfig.Channel = ADC_CHANNEL_17;
  sConfig.Rank = ADC_REGULAR_RANK_4;
  if (HAL_ADC_ConfigChannel(&hadc1, &sConfig) != HAL_OK)
  {
    Error_Handler();
  }

  /** Configure Regular Channel
  */
  sConfig.Channel = ADC_CHANNEL_5;
  sConfig.Rank = ADC_REGULAR_RANK_5;
  if (HAL_ADC_ConfigChannel(&hadc1, &sConfig) != HAL_OK)
  {
    Error_Handler();
  }

}

static void MX_ADC3_Init(void)
{

  ADC_ChannelConfTypeDef sConfig = {0};

  /** Common config
  */
  hadc3.Instance = ADC3;
  hadc3.Init.ClockPrescaler = ADC_CLOCK_ASYNC_DIV16;
  hadc3.Init.Resolution = ADC_RESOLUTION_12B;
  hadc3.Init.ScanConvMode = ADC_SCAN_ENABLE;
  hadc3.Init.EOCSelection = ADC_EOC_SEQ_CONV;
  hadc3.Init.LowPowerAutoWait = DISABLE;
  hadc3.Init.ContinuousConvMode = ENABLE;
  hadc3.Init.NbrOfConversion = 7;
  hadc3.Init.DiscontinuousConvMode = DISABLE;
  hadc3.Init.ExternalTrigConv = ADC_SOFTWARE_START;
  hadc3.Init.ExternalTrigConvEdge = ADC_EXTERNALTRIGCONVEDGE_NONE;
  hadc3.Init.ConversionDataManagement = ADC_CONVERSIONDATA_DMA_CIRCULAR;
  hadc3.Init.Overrun = ADC_OVR_DATA_OVERWRITTEN;
  hadc3.Init.LeftBitShift = ADC_LEFTBITSHIFT_NONE;
  hadc3.Init.OversamplingMode = DISABLE;
  if (HAL_ADC_Init(&hadc3) != HAL_OK)
  {
    Error_Handler();
  }

  /** Configure Regular Channel
  */
  sConfig.Channel = ADC_CHANNEL_1;
  sConfig.Rank = ADC_REGULAR_RANK_1;
  sConfig.SamplingTime = ADC_SAMPLETIME_387CYCLES_5;
  sConfig.SingleDiff = ADC_SINGLE_ENDED;
  sConfig.OffsetNumber = ADC_OFFSET_NONE;
  sConfig.Offset = 0;
  sConfig.OffsetSignedSaturation = DISABLE;
  if (HAL_ADC_ConfigChannel(&hadc3, &sConfig) != HAL_OK)
  {
    Error_Handler();
  }

  /** Configure Regular Channel
  */
  sConfig.Channel = ADC_CHANNEL_0;
  sConfig.Rank = ADC_REGULAR_RANK_2;
  if (HAL_ADC_ConfigChannel(&hadc3, &sConfig) != HAL_OK)
  {
    Error_Handler();
  }

  /** Configure Regular Channel
  */
  sConfig.Channel = ADC_CHANNEL_11;
  sConfig.Rank = ADC_REGULAR_RANK_3;
  if (HAL_ADC_ConfigChannel(&hadc3, &sConfig) != HAL_OK)
  {
    Error_Handler();
  }

  /** Configure Regular Channel
  */
  sConfig.Channel = ADC_CHANNEL_6;
  sConfig.Rank = ADC_REGULAR_RANK_4;
  if (HAL_ADC_ConfigChannel(&hadc3, &sConfig) != HAL_OK)
  {
    Error_Handler();
  }

  /** Configure Regular Channel
  */
  sConfig.Channel = ADC_CHANNEL_3;
  sConfig.Rank = ADC_REGULAR_RANK_5;
  if (HAL_ADC_ConfigChannel(&hadc3, &sConfig) != HAL_OK)
  {
    Error_Handler();
  }

  /** Configure Regular Channel
  */
  sConfig.Channel = ADC_CHANNEL_7;
  sConfig.Rank = ADC_REGULAR_RANK_6;
  if (HAL_ADC_ConfigChannel(&hadc3, &sConfig) != HAL_OK)
  {
    Error_Handler();
  }

  /** Configure Regular Channel
  */
  sConfig.Channel = ADC_CHANNEL_2;
  sConfig.Rank = ADC_REGULAR_RANK_7;
  if (HAL_ADC_ConfigChannel(&hadc3, &sConfig) != HAL_OK)
  {
    Error_Handler();
  }

}

static void MX_DAC1_Init(void)
{

  DAC_ChannelConfTypeDef sConfig = {0};

  /** DAC Initialization
  */
  hdac1.Instance = DAC1;
  if (HAL_DAC_Init(&hdac1) != HAL_OK)
  {
    Error_Handler();
  }

  /** DAC channel OUT1 config
  */
  sConfig.DAC_SampleAndHold = DAC_SAMPLEANDHOLD_DISABLE;
  sConfig.DAC_Trigger = DAC_TRIGGER_NONE;
  sConfig.DAC_OutputBuffer = DAC_OUTPUTBUFFER_ENABLE;
  sConfig.DAC_ConnectOnChipPeripheral = DAC_CHIPCONNECT_DISABLE;
  sConfig.DAC_UserTrimming = DAC_TRIMMING_FACTORY;
  if (HAL_DAC_ConfigChannel(&hdac1, &sConfig, DAC_CHANNEL_1) != HAL_OK)
  {
    Error_Handler();
  }

  /** DAC channel OUT2 config
  */
  if (HAL_DAC_ConfigChannel(&hdac1, &sConfig, DAC_CHANNEL_2) != HAL_OK)
  {
    Error_Handler();
  }

}

static void MX_RTC_Init(void)
{

  /** Initialize RTC Only
  */
  hrtc.Instance = RTC;
  hrtc.Init.HourFormat = RTC_HOURFORMAT_24;
  hrtc.Init.AsynchPrediv = 127;
  hrtc.Init.SynchPrediv = 255;
  hrtc.Init.OutPut = RTC_OUTPUT_DISABLE;
  hrtc.Init.OutPutPolarity = RTC_OUTPUT_POLARITY_HIGH;
  hrtc.Init.OutPutType = RTC_OUTPUT_TYPE_OPENDRAIN;
  hrtc.Init.OutPutRemap = RTC_OUTPUT_REMAP_NONE;
  if (HAL_RTC_Init(&hrtc) != HAL_OK)
  {
    Error_Handler();
  }

}

static void MX_SAI1_Init(void)
{

  hsai_BlockA1.Instance = SAI1_Block_A;
  hsai_BlockA1.Init.AudioMode = SAI_MODESLAVE_TX;
  hsai_BlockA1.Init.Synchro = SAI_ASYNCHRONOUS;
  hsai_BlockA1.Init.OutputDrive = SAI_OUTPUTDRIVE_DISABLE;
  hsai_BlockA1.Init.FIFOThreshold = SAI_FIFOTHRESHOLD_EMPTY;
  hsai_BlockA1.Init.SynchroExt = SAI_SYNCEXT_DISABLE;
  hsai_BlockA1.Init.MonoStereoMode = SAI_STEREOMODE;
  hsai_BlockA1.Init.CompandingMode = SAI_NOCOMPANDING;
  hsai_BlockA1.Init.TriState = SAI_OUTPUT_NOTRELEASED;
  if (HAL_SAI_InitProtocol(&hsai_BlockA1, SAI_I2S_STANDARD, SAI_PROTOCOL_DATASIZE_24BIT, 2) != HAL_OK)
  {
    Error_Handler();
  }
  hsai_BlockB1.Instance = SAI1_Block_B;
  hsai_BlockB1.Init.AudioMode = SAI_MODESLAVE_RX;
  hsai_BlockB1.Init.Synchro = SAI_SYNCHRONOUS;
  hsai_BlockB1.Init.OutputDrive = SAI_OUTPUTDRIVE_DISABLE;
  hsai_BlockB1.Init.FIFOThreshold = SAI_FIFOTHRESHOLD_EMPTY;
  hsai_BlockB1.Init.SynchroExt = SAI_SYNCEXT_DISABLE;
  hsai_BlockB1.Init.MonoStereoMode = SAI_STEREOMODE;
  hsai_BlockB1.Init.CompandingMode = SAI_NOCOMPANDING;
  hsai_BlockB1.Init.TriState = SAI_OUTPUT_NOTRELEASED;
  if (HAL_SAI_InitProtocol(&hsai_BlockB1, SAI_I2S_STANDARD, SAI_PROTOCOL_DATASIZE_24BIT, 2) != HAL_OK)
  {
    Error_Handler();
  }

}

static void MX_SPI1_Init(void)
{

  /* SPI1 parameter configuration*/
  hspi1.Instance = SPI1;
  hspi1.Init.Mode = SPI_MODE_MASTER;
  hspi1.Init.Direction = SPI_DIRECTION_2LINES;
  hspi1.Init.DataSize = SPI_DATASIZE_8BIT;
  hspi1.Init.CLKPolarity = SPI_POLARITY_LOW;
  hspi1.Init.CLKPhase = SPI_PHASE_1EDGE;
  hspi1.Init.NSS = SPI_NSS_SOFT;
  hspi1.Init.BaudRatePrescaler = SPI_BAUDRATEPRESCALER_2;
  hspi1.Init.FirstBit = SPI_FIRSTBIT_MSB;
  hspi1.Init.TIMode = SPI_TIMODE_DISABLE;
  hspi1.Init.CRCCalculation = SPI_CRCCALCULATION_DISABLE;
  hspi1.Init.CRCPolynomial = 0x0;
  hspi1.Init.NSSPMode = SPI_NSS_PULSE_DISABLE;
  hspi1.Init.NSSPolarity = SPI_NSS_POLARITY_LOW;
  hspi1.Init.FifoThreshold = SPI_FIFO_THRESHOLD_01DATA;
  hspi1.Init.TxCRCInitializationPattern = SPI_CRC_INITIALIZATION_ALL_ZERO_PATTERN;
  hspi1.Init.RxCRCInitializationPattern = SPI_CRC_INITIALIZATION_ALL_ZERO_PATTERN;
  hspi1.Init.MasterSSIdleness = SPI_MASTER_SS_IDLENESS_00CYCLE;
  hspi1.Init.MasterInterDataIdleness = SPI_MASTER_INTERDATA_IDLENESS_00CYCLE;
  hspi1.Init.MasterReceiverAutoSusp = SPI_MASTER_RX_AUTOSUSP_DISABLE;
  hspi1.Init.MasterKeepIOState = SPI_MASTER_KEEP_IO_STATE_DISABLE;
  hspi1.Init.IOSwap = SPI_IO_SWAP_DISABLE;
  if (HAL_SPI_Init(&hspi1) != HAL_OK)
  {
    Error_Handler();
  }

}

static void MX_SPI4_Init(void)
{

  /* SPI4 parameter configuration*/
  hspi4.Instance = SPI4;
  hspi4.Init.Mode = SPI_MODE_MASTER;
  hspi4.Init.Direction = SPI_DIRECTION_2LINES_TXONLY;
  hspi4.Init.DataSize = SPI_DATASIZE_8BIT;
  hspi4.Init.CLKPolarity = SPI_POLARITY_LOW;
  hspi4.Init.CLKPhase = SPI_PHASE_1EDGE;
  hspi4.Init.NSS = SPI_NSS_SOFT;
  hspi4.Init.BaudRatePrescaler = SPI_BAUDRATEPRESCALER_32;
  hspi4.Init.FirstBit = SPI_FIRSTBIT_MSB;
  hspi4.Init.TIMode = SPI_TIMODE_DISABLE;
  hspi4.Init.CRCCalculation = SPI_CRCCALCULATION_DISABLE;
  hspi4.Init.CRCPolynomial = 0x0;
  hspi4.Init.NSSPMode = SPI_NSS_PULSE_DISABLE;
  hspi4.Init.NSSPolarity = SPI_NSS_POLARITY_LOW;
  hspi4.Init.FifoThreshold = SPI_FIFO_THRESHOLD_01DATA;
  hspi4.Init.TxCRCInitializationPattern = SPI_CRC_INITIALIZATION_ALL_ZERO_PATTERN;
  hspi4.Init.RxCRCInitializationPattern = SPI_CRC_INITIALIZATION_ALL_ZERO_PATTERN;
  hspi4.Init.MasterSSIdleness = SPI_MASTER_SS_IDLENESS_00CYCLE;
  hspi4.Init.MasterInterDataIdleness = SPI_MASTER_INTERDATA_IDLENESS_00CYCLE;
  hspi4.Init.MasterReceiverAutoSusp = SPI_MASTER_RX_AUTOSUSP_DISABLE;
  hspi4.Init.MasterKeepIOState = SPI_MASTER_KEEP_IO_STATE_DISABLE;
  hspi4.Init.IOSwap = SPI_IO_SWAP_DISABLE;
  if (HAL_SPI_Init(&hspi4) != HAL_OK)
  {
    Error_Handler();
  }

}

static void MX_USART6_UART_Init(void)
{

  huart6.Instance = USART6;
  huart6.Init.BaudRate = 115200;
  huart6.Init.WordLength = UART_WORDLENGTH_8B;
  huart6.Init.StopBits = UART_STOPBITS_1;
  huart6.Init.Parity = UART_PARITY_NONE;
  huart6.Init.Mode = UART_MODE_RX;
  huart6.Init.HwFlowCtl = UART_HWCONTROL_NONE;
  huart6.Init.OverSampling = UART_OVERSAMPLING_16;
  huart6.Init.OneBitSampling = UART_ONE_BIT_SAMPLE_DISABLE;
  huart6.Init.ClockPrescaler = UART_PRESCALER_DIV1;
  huart6.AdvancedInit.AdvFeatureInit = UART_ADVFEATURE_NO_INIT;
  if (HAL_UART_Init(&huart6) != HAL_OK)
  {
    Error_Handler();
  }
  if (HAL_UARTEx_SetTxFifoThreshold(&huart6, UART_TXFIFO_THRESHOLD_1_8) != HAL_OK)
  {
    Error_Handler();
  }
  if (HAL_UARTEx_SetRxFifoThreshold(&huart6, UART_RXFIFO_THRESHOLD_1_8) != HAL_OK)
  {
    Error_Handler();
  }
  if (HAL_UARTEx_DisableFifoMode(&huart6) != HAL_OK)
  {
    Error_Handler();
  }

}

static void MX_USB_OTG_FS_PCD_Init(void)
{

  hpcd_USB_OTG_FS.Instance = USB_OTG_FS;
  hpcd_USB_OTG_FS.Init.dev_endpoints = 9;
  hpcd_USB_OTG_FS.Init.speed = PCD_SPEED_FULL;
  hpcd_USB_OTG_FS.Init.dma_enable = DISABLE;
  hpcd_USB_OTG_FS.Init.phy_itface = PCD_PHY_EMBEDDED;
  hpcd_USB_OTG_FS.Init.Sof_enable = DISABLE;
  hpcd_USB_OTG_FS.Init.low_power_enable = DISABLE;
  hpcd_USB_OTG_FS.Init.lpm_enable = DISABLE;
  hpcd_USB_OTG_FS.Init.battery_charging_enable = DISABLE;
  hpcd_USB_OTG_FS.Init.vbus_sensing_enable = DISABLE;
  hpcd_USB_OTG_FS.Init.use_dedicated_ep1 = DISABLE;
  if (HAL_PCD_Init(&hpcd_USB_OTG_FS) != HAL_OK)
  {
    Error_Handler();
  }

}

static void MX_USB_OTG_HS_HCD_Init(void)
{

  hhcd_USB_OTG_HS.Instance = USB_OTG_HS;
  hhcd_USB_OTG_HS.Init.Host_channels = 16;
  hhcd_USB_OTG_HS.Init.speed = HCD_SPEED_FULL;
  hhcd_USB_OTG_HS.Init.dma_enable = DISABLE;
  hhcd_USB_OTG_HS.Init.phy_itface = USB_OTG_EMBEDDED_PHY;
  hhcd_USB_OTG_HS.Init.Sof_enable = DISABLE;
  hhcd_USB_OTG_HS.Init.low_power_enable = DISABLE;
  hhcd_USB_OTG_HS.Init.use_external_vbus = DISABLE;
  if (HAL_HCD_Init(&hhcd_USB_OTG_HS) != HAL_OK)
  {
    Error_Handler();
  }

}

static void MX_DMA_Init(void)
{

  /* DMA controller clock enable */
  __HAL_RCC_DMA2_CLK_ENABLE();
  __HAL_RCC_DMA1_CLK_ENABLE();

  /* DMA interrupt init */
  /* DMA1_Stream0_IRQn interrupt configuration */
  HAL_NVIC_SetPriority(DMA1_Stream0_IRQn, 5, 0);
  HAL_NVIC_EnableIRQ(DMA1_Stream0_IRQn);
  /* DMA1_Stream1_IRQn interrupt configuration */
  HAL_NVIC_SetPriority(DMA1_Stream1_IRQn, 5, 0);
  HAL_NVIC_EnableIRQ(DMA1_Stream1_IRQn);
  /* DMA2_Stream1_IRQn interrupt configuration */
  HAL_NVIC_SetPriority(DMA2_Stream1_IRQn, 5, 0);
  HAL_NVIC_EnableIRQ(DMA2_Stream1_IRQn);
  /* DMA2_Stream4_IRQn interrupt configuration */
  HAL_NVIC_SetPriority(DMA2_Stream4_IRQn, 5, 0);
  HAL_NVIC_EnableIRQ(DMA2_Stream4_IRQn);

}

/* FMC initialization function */
static void MX_FMC_Init(void)
{

  FMC_SDRAM_TimingTypeDef SdramTiming = {0};

  /** Perform the SDRAM1 memory initialization sequence
  */
  hsdram1.Instance = FMC_SDRAM_DEVICE;
  /* hsdram1.Init */
  hsdram1.Init.SDBank = FMC_SDRAM_BANK2;
  hsdram1.Init.ColumnBitsNumber = FMC_SDRAM_COLUMN_BITS_NUM_8;
  hsdram1.Init.RowBitsNumber = FMC_SDRAM_ROW_BITS_NUM_12;
  hsdram1.Init.MemoryDataWidth = FMC_SDRAM_MEM_BUS_WIDTH_16;
  hsdram1.Init.InternalBankNumber = FMC_SDRAM_INTERN_BANKS_NUM_4;
  hsdram1.Init.CASLatency = FMC_SDRAM_CAS_LATENCY_3;
  hsdram1.Init.WriteProtection = FMC_SDRAM_WRITE_PROTECTION_DISABLE;
  hsdram1.Init.SDClockPeriod = FMC_SDRAM_CLOCK_PERIOD_2;
  hsdram1.Init.ReadBurst = FMC_SDRAM_RBURST_ENABLE;
  hsdram1.Init.ReadPipeDelay = FMC_SDRAM_RPIPE_DELAY_0;
  /* SdramTiming */
  SdramTiming.LoadToActiveDelay = 2;
  SdramTiming.ExitSelfRefreshDelay = 6;
  SdramTiming.SelfRefreshTime = 4;
  SdramTiming.RowCycleDelay = 6;
  SdramTiming.WriteRecoveryTime = 2;
  SdramTiming.RPDelay = 2;
  SdramTiming.RCDDelay = 2;

  if (HAL_SDRAM_Init(&hsdram1, &SdramTiming) != HAL_OK)
  {
    Error_Handler( );
  }

}

static void MX_GPIO_Init(void)
{
  GPIO_InitTypeDef GPIO_InitStruct = {0};

  /* GPIO Ports Clock Enable */
  __HAL_RCC_GPIOE_CLK_ENABLE();
  __HAL_RCC_GPIOC_CLK_ENABLE();
  __HAL_RCC_GPIOF_CLK_ENABLE();
  __HAL_RCC_GPIOH_CLK_ENABLE();
  __HAL_RCC_GPIOA_CLK_ENABLE();
  __HAL_RCC_GPIOB_CLK_ENABLE();
  __HAL_RCC_GPIOG_CLK_ENABLE();
  __HAL_RCC_GPIOD_CLK_ENABLE();

  /*Configure GPIO pin Output Level */
  HAL_GPIO_WritePin(GPIOC, EXTSPI_nCS_Pin|FLASH_HOLD_Pin|FLASH_nCS_Pin|RECORD_BUTTON_LED_Pin
                          |MUX_A_Pin|MUX_B_Pin|CU_UP_LED_Pin, GPIO_PIN_RESET);

  /*Configure GPIO pin Output Level */
  HAL_GPIO_WritePin(GPIOB, FLASH_WP_Pin|CU_DOWN_LED_Pin|CS_CS_Pin|CS_RST_Pin
                          |USB_HOST_PWR_EN_Pin|SYNC_LED_Pin|SHIFT_LED_Pin|MOD_CV_GREEN_LED_Pin, GPIO_PIN_RESET);

  /*Configure GPIO pin Output Level */
  HAL_GPIO_WritePin(GPIOA, RANDOM_BUTTON_LED_Pin|INLEVELRED_LED_Pin, GPIO_PIN_RESET);

  /*Configure GPIO pin Output Level */
  HAL_GPIO_WritePin(MOD_CV_RED_LED_GPIO_Port, MOD_CV_RED_LED_Pin, GPIO_PIN_RESET);

  /*Configure GPIO pin Output Level */
  HAL_GPIO_WritePin(MUX_C_GPIO_Port, MUX_C_Pin, GPIO_PIN_RESET);

  /*Configure GPIO pins : RANDOM_AMOUNT_SWITCH1_Pin RANDOM_AMOUNT_SWITCH2_Pin */
  GPIO_InitStruct.Pin = RANDOM_AMOUNT_SWITCH1_Pin|RANDOM_AMOUNT_SWITCH2_Pin;
  GPIO_InitStruct.Mode = GPIO_MODE_INPUT;
  GPIO_InitStruct.Pull = GPIO_PULLUP;
  HAL_GPIO_Init(GPIOC, &GPIO_InitStruct);

  /*Configure GPIO pins : EXTSPI_nCS_Pin FLASH_HOLD_Pin FLASH_nCS_Pin RECORD_BUTTON_LED_Pin
                           MUX_A_Pin MUX_B_Pin CU_UP_LED_Pin */
  GPIO_InitStruct.Pin = EXTSPI_nCS_Pin|FLASH_HOLD_Pin|FLASH_nCS_Pin|RECORD_BUTTON_LED_Pin
                          |MUX_A_Pin|MUX_B_Pin|CU_UP_LED_Pin;
  GPIO_InitStruct.Mode = GPIO_MODE_OUTPUT_PP;
  GPIO_InitStruct.Pull = GPIO_NOPULL;
  GPIO_InitStruct.Speed = GPIO_SPEED_FREQ_LOW;
  HAL_GPIO_Init(GPIOC, &GPIO_InitStruct);

  /*Configure GPIO pin : PF6 */
  GPIO_InitStruct.Pin = GPIO_PIN_6;
  GPIO_InitStruct.Mode = GPIO_MODE_ANALOG;
  GPIO_InitStruct.Pull = GPIO_NOPULL;
  HAL_GPIO_Init(GPIOF, &GPIO_InitStruct);

  /*Configure GPIO pins : FLASH_WP_Pin CU_DOWN_LED_Pin CS_CS_Pin CS_RST_Pin
                           USB_HOST_PWR_EN_Pin SYNC_LED_Pin SHIFT_LED_Pin MOD_CV_GREEN_LED_Pin */
  GPIO_InitStruct.Pin = FLASH_WP_Pin|CU_DOWN_LED_Pin|CS_CS_Pin|CS_RST_Pin
                          |USB_HOST_PWR_EN_Pin|SYNC_LED_Pin|SHIFT_LED_Pin|MOD_CV_GREEN_LED_Pin;
  GPIO_InitStruct.Mode = GPIO_MODE_OUTPUT_PP;
  GPIO_InitStruct.Pull = GPIO_NOPULL;
  GPIO_InitStruct.Speed = GPIO_SPEED_FREQ_LOW;
  HAL_GPIO_Init(GPIOB, &GPIO_InitStruct);

  /*Configure GPIO pins : USB_HOST_PWR_FAULT_Pin MOD_CV_BUTTON_Pin */
  GPIO_InitStruct.Pin = USB_HOST_PWR_FAULT_Pin|MOD_CV_BUTTON_Pin;
  GPIO_InitStruct.Mode = GPIO_MODE_INPUT;
  GPIO_InitStruct.Pull = GPIO_PULLUP;
  HAL_GPIO_Init(GPIOB, &GPIO_InitStruct);

  /*Configure GPIO pins : RECORD_GATE_Pin RECORD_BUTTON_Pin SYNC_GATE_Pin */
  GPIO_InitStruct.Pin = RECORD_GATE_Pin|RECORD_BUTTON_Pin|SYNC_GATE_Pin;
  GPIO_InitStruct.Mode = GPIO_MODE_IT_RISING_FALLING;
  GPIO_InitStruct.Pull = GPIO_PULLUP;
  HAL_GPIO_Init(GPIOD, &GPIO_InitStruct);

  /*Configure GPIO pins : PG2 PG3 PG6 PG7
                           PG10 */
  GPIO_InitStruct.Pin = GPIO_PIN_2|GPIO_PIN_3|GPIO_PIN_6|GPIO_PIN_7
                          |GPIO_PIN_10;
  GPIO_InitStruct.Mode = GPIO_MODE_ANALOG;
  GPIO_InitStruct.Pull = GPIO_NOPULL;
  HAL_GPIO_Init(GPIOG, &GPIO_InitStruct);

  /*Configure GPIO pin : PC7 */
  GPIO_InitStruct.Pin = GPIO_PIN_7;
  GPIO_InitStruct.Mode = GPIO_MODE_ANALOG;
  GPIO_InitStruct.Pull = GPIO_NOPULL;
  HAL_GPIO_Init(GPIOC, &GPIO_InitStruct);

  /*Configure GPIO pin : PREPOST_SWITCH_Pin */
  GPIO_InitStruct.Pin = PREPOST_SWITCH_Pin;
  GPIO_InitStruct.Mode = GPIO_MODE_IT_RISING_FALLING;
  GPIO_InitStruct.Pull = GPIO_PULLUP;
  HAL_GPIO_Init(PREPOST_SWITCH_GPIO_Port, &GPIO_InitStruct);

  /*Configure GPIO pins : RANDOM_BUTTON_LED_Pin INLEVELRED_LED_Pin */
  GPIO_InitStruct.Pin = RANDOM_BUTTON_LED_Pin|INLEVELRED_LED_Pin;
  GPIO_InitStruct.Mode = GPIO_MODE_OUTPUT_PP;
  GPIO_InitStruct.Pull = GPIO_NOPULL;
  GPIO_InitStruct.Speed = GPIO_SPEED_FREQ_LOW;
  HAL_GPIO_Init(GPIOA, &GPIO_InitStruct);

  /*Configure GPIO pins : PA9 PA10 */
  GPIO_InitStruct.Pin = GPIO_PIN_9|GPIO_PIN_10;
  GPIO_InitStruct.Mode = GPIO_MODE_ANALOG;
  GPIO_InitStruct.Pull = GPIO_NOPULL;
  HAL_GPIO_Init(GPIOA, &GPIO_InitStruct);

  /*Configure GPIO pin : SHIFT_BUTTON_Pin */
  GPIO_InitStruct.Pin = SHIFT_BUTTON_Pin;
  GPIO_InitStruct.Mode = GPIO_MODE_INPUT;
  GPIO_InitStruct.Pull = GPIO_PULLUP;
  HAL_GPIO_Init(SHIFT_BUTTON_GPIO_Port, &GPIO_InitStruct);

  /*Configure GPIO pins : PD3 PD4 PD5 */
  GPIO_InitStruct.Pin = GPIO_PIN_3|GPIO_PIN_4|GPIO_PIN_5;
  GPIO_InitStruct.Mode = GPIO_MODE_ANALOG;
  GPIO_InitStruct.Pull = GPIO_NOPULL;
  HAL_GPIO_Init(GPIOD, &GPIO_InitStruct);

  /*Configure GPIO pin : MOD_CV_RED_LED_Pin */
  GPIO_InitStruct.Pin = MOD_CV_RED_LED_Pin;
  GPIO_InitStruct.Mode = GPIO_MODE_OUTPUT_PP;
  GPIO_InitStruct.Pull = GPIO_NOPULL;
  GPIO_InitStruct.Speed = GPIO_SPEED_FREQ_LOW;
  HAL_GPIO_Init(MOD_CV_RED_LED_GPIO_Port, &GPIO_InitStruct);

  /*Configure GPIO pin : MUX_C_Pin */
  GPIO_InitStruct.Pin = MUX_C_Pin;
  GPIO_InitStruct.Mode = GPIO_MODE_OUTPUT_PP;
  GPIO_InitStruct.Pull = GPIO_NOPULL;
  GPIO_InitStruct.Speed = GPIO_SPEED_FREQ_LOW;
  HAL_GPIO_Init(MUX_C_GPIO_Port, &GPIO_InitStruct);

  /*Configure GPIO pins : SSWT_SWITCH_Pin RANDOM_BUTTON_Pin */
  GPIO_InitStruct.Pin = SSWT_SWITCH_Pin|RANDOM_BUTTON_Pin;
  GPIO_InitStruct.Mode = GPIO_MODE_INPUT;
  GPIO_InitStruct.Pull = GPIO_PULLUP;
  HAL_GPIO_Init(GPIOG, &GPIO_InitStruct);

  /*Configure GPIO pin : RANDOM_GATE_Pin */
  GPIO_InitStruct.Pin = RANDOM_GATE_Pin;
  GPIO_InitStruct.Mode = GPIO_MODE_IT_RISING_FALLING;
  GPIO_InitStruct.Pull = GPIO_PULLUP;
  HAL_GPIO_Init(RANDOM_GATE_GPIO_Port, &GPIO_InitStruct);

  /* EXTI interrupt init*/
  HAL_NVIC_SetPriority(EXTI9_5_IRQn, 15, 0);
  HAL_NVIC_EnableIRQ(EXTI9_5_IRQn);

  HAL_NVIC_SetPriority(EXTI15_10_IRQn, 15, 0);
  HAL_NVIC_EnableIRQ(EXTI15_10_IRQn);

}

void StartDefaultTask(void const * argument)
{
  /* USER CODE BEGIN 5 */
  setup();

  /* Infinite loop */
  for(;;) {
    loop();
  }
  /* USER CODE END 5 */
}

void Error_Handler(void)
{
  /* USER CODE BEGIN Error_Handler_Debug */
  /* User can add his own implementation to report the HAL error return state */
#ifdef DEBUG
  __asm__("BKPT");
#else
  NVIC_SystemReset();
#endif
  /* USER CODE END Error_Handler_Debug */
}

#ifdef  USE_FULL_ASSERT
/**
  * @brief  Reports the name of the source file and the source line number
  *         where the assert_param error has occurred.
  * @param  file: pointer to the source file name
  * @param  line: assert_param error line source number
  * @retval None
  */
void assert_failed(uint8_t *file, uint32_t line)
{
  /* USER CODE BEGIN 6 */
#ifdef DEBUG
  __asm__("BKPT");
#else
  NVIC_SystemReset();
#endif
  /* USER CODE END 6 */
}
#endif /* USE_FULL_ASSERT */
